AUTOSAR XML (schema 00048)
package /AUTOLIV/SoftwareComponents/EOL
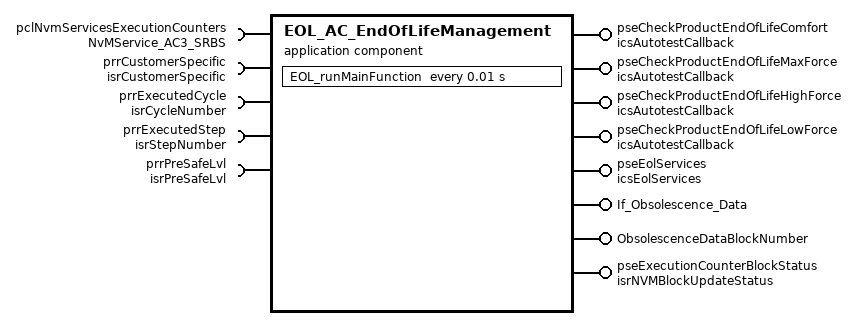
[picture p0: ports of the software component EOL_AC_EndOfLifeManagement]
  application sw component type EOL_AC_EndOfLifeManagement
    4 x require port:
      pclNvmServicesExecutionCounters: required-com-specs=[EraseBlock, InvalidateNvBlock, WriteBlock, ReadBlock, SetRamBlockStatus, GetErrorStatus], required-interface=NvMService_AC3_SRBS
      prrCustomerSpecific: required-interface=isrCustomerSpecific
        required-com-specs:
          data-element=b8HardReleaseRequest
          data-element=b8IsCarCrankingActive
          data-element=b8IsCarCrashDetected
          data-element=b8IsTrigOffEventAllowed
          data-element=b8PreCrashRequestEnable
          data-element=u8BeltSlackStatus
          data-element=u8HapticRequest
          data-element=u8PreCrashRequest
          data-element=u8TriggerRequest, filter=data-filter-type=ALWAYS
          data-element=b8SignalRelInhibition
      prrExecutedCycle: nonqueued-receiver-com-spec{data-element=u8CycleNumber, init-value=constant-reference=APPLINIT_KU8_CYCLE_NUMBER_NONE}, required-interface=isrCycleNumber
      prrExecutedStep: nonqueued-receiver-com-spec=data-element=u8StepNumber, required-interface=isrStepNumber
    6 x provide port:
      pseCheckProductEndOfLifeComfort: server-com-spec{operation=AutotestCallback, queue-length=1}, provided-interface=icsAutotestCallback
      pseCheckProductEndOfLifeMaxForce: server-com-spec{operation=AutotestCallback, queue-length=1}, provided-interface=icsAutotestCallback
      pseCheckProductEndOfLifeHighForce: server-com-spec{operation=AutotestCallback, queue-length=1}, provided-interface=icsAutotestCallback
      pseCheckProductEndOfLifeLowForce: server-com-spec{operation=AutotestCallback, queue-length=1}, provided-interface=icsAutotestCallback
      pseEolServices: server-com-spec{operation=SetCycleCounterDatasetIndex, queue-length=1}, provided-interface=icsEolServices
      If_Obsolescence_Data: provided-com-specs=[{operation=Write_Data, queue-length=1}, {operation=Get_Data, queue-length=1}], provided-interface=If_Obsolescence_Data
    require port prrPreSafeLvl: nonqueued-receiver-com-spec{data-element=u8PreSafeLvl, filter=data-filter-type=ALWAYS, init-value=constant-reference=APPLINIT_KU8_PRESAFE_NOLVL}, required-interface=isrPreSafeLvl
    provide port ObsolescenceDataBlockNumber: nonqueued-sender-com-spec{data-element=BlockNumber, init-value=0}, provided-interface=ObsolescenceDataBlockNumber
    provide port pseExecutionCounterBlockStatus: nonqueued-sender-com-spec=b8NVMBlockStatus, provided-interface=isrNVMBlockUpdateStatus
    behavior EOL_IB_EndOfLifeManagement: data-type-mapping=[DataTypeMappingSet_PP4G, DataTypeMappings_DEV]
      ar-typed-per-instance-memorys:
        data PerInstanceMemory: sw-calibration-access=READ-ONLY, type=uint16
      4 x operation invoked event:
        oie_pseCheckProductEndOfLifeComfort_AutotestCallback: start-on-event=EOL_Autotest_CheckProductEndOfLifeComfort, operation=pseCheckProductEndOfLifeComfort.AutotestCallback
        oie_pseCheckProductEndOfLifeMaxForce_AutotestCallback: start-on-event=EOL_Autotest_CheckProductEndOfLifeMaxForce, operation=pseCheckProductEndOfLifeMaxForce.AutotestCallback
        oie_pseCheckProductEndOfLifeHighForce_AutotestCallback: start-on-event=EOL_Autotest_CheckProductEndOfLifeHighForce, operation=pseCheckProductEndOfLifeHighForce.AutotestCallback
        oie_pseCheckProductEndOfLifeLowForce_AutotestCallback: start-on-event=EOL_Autotest_CheckProductEndOfLifeLowForce, operation=pseCheckProductEndOfLifeLowForce.AutotestCallback
      timing event EOL_evMainFunction: start-on-event=EOL_runMainFunction, period=0.01
      operation invoked event oie_pseEolServices_SetCycleCounterDatasetIndex: start-on-event=EOL_runSetDatasetIndex, operation=pseEolServices.SetCycleCounterDatasetIndex
      operation invoked event OIT_EOL_Write_Obsolescence_Data_If_Obsolescence_Data_Write_Data: start-on-event=EOL_Write_Obsolescence_Data, operation=If_Obsolescence_Data.Write_Data
      operation invoked event OIT_EOL_Get_Obsolescence_Data_If_Obsolescence_Data_Get_Data: start-on-event=EOL_Get_Obsolescence_Data, operation=If_Obsolescence_Data.Get_Data
      9 x runnable:
        EOL_Autotest_CheckProductEndOfLifeComfort: can-be-invoked-concurrently=true
        EOL_Autotest_CheckProductEndOfLifeMaxForce: can-be-invoked-concurrently=true
        EOL_Autotest_CheckProductEndOfLifeHighForce: can-be-invoked-concurrently=true
        EOL_Autotest_CheckProductEndOfLifeLowForce: can-be-invoked-concurrently=true
        EOL_Init
        EOL_runMainFunction
          data-receive-point-by-arguments:
            5 x access:
              DRP_prrExecutedCycle_u8CycleNumber: accessed-variable=prrExecutedCycle.u8CycleNumber
              drparg_b8IsTrigOffEventAllow: accessed-variable=prrCustomerSpecific.b8IsTrigOffEventAllowed
              drparg_u8StepNumber: accessed-variable=prrExecutedStep.u8StepNumber
              REC_prrCustomerSpecific_u8TriggerRequest: accessed-variable=prrCustomerSpecific.u8TriggerRequest
              REC_prrPreSafeLvl_u8PreSafeLvl: accessed-variable=prrPreSafeLvl.u8PreSafeLvl
          data-send-points:
            access SEND_pseExecutionCounterBlockStatus_b8NVMBlockStatus: accessed-variable=pseExecutionCounterBlockStatus.b8NVMBlockStatus
          sync call SC_pclNvmServicesExecutionCounters_SetRamBlockStatus: operation=pclNvmServicesExecutionCounters.SetRamBlockStatus
        EOL_runSetDatasetIndex: can-be-invoked-concurrently=true
        EOL_Write_Obsolescence_Data
        EOL_Get_Obsolescence_Data: can-be-invoked-concurrently=true
          data-send-points:
            access SEND_ObsolescenceDataBlockNumber_BlockNumber: accessed-variable=ObsolescenceDataBlockNumber.BlockNumber
  swc implementation EOL_impEndOfLifeManagement: behavior=EOL_IB_EndOfLifeManagement
    code-descriptors:
      code EOL_Impl_Code: artifact-descriptors=autosar-engineering-object=category=SWSRC
